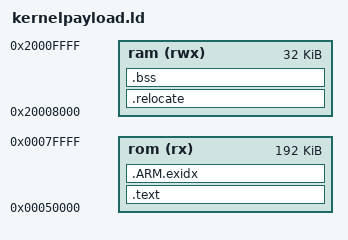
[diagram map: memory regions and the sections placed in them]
/*
 * This file is part of StormLoader, the Storm Bootloader
 *
 * StormLoader is free software: you can redistribute it and/or modify
 * it under the terms of the GNU General Public License as published by
 * the Free Software Foundation, either version 3 of the License, or
 * (at your option) any later version.
 *
 * StormLoader is distributed in the hope that it will be useful,
 * but WITHOUT ANY WARRANTY; without even the implied warranty of
 * MERCHANTABILITY or FITNESS FOR A PARTICULAR PURPOSE.  See the
 * GNU General Public License for more details.
 *
 * You should have received a copy of the GNU General Public License
 * along with Foobar.  If not, see <http://www.gnu.org/licenses/>.
 *  
 * Copyright 2014, Michael Andersen <m.andersen@eecs.berkeley.edu>
 *
 * This file is largely copied from the Atmel supplied linker scripts
 */

OUTPUT_FORMAT("elf32-littlearm", "elf32-littlearm", "elf32-littlearm")
OUTPUT_ARCH(arm)
SEARCH_DIR(.) 

/* Memory Spaces Definitions, 448K flash, 64K ram */
MEMORY
{
  rom (rx)  : ORIGIN = 0x00050000, LENGTH = 0x00030000
  ram (rwx) : ORIGIN = 0x20008000, LENGTH = 0x00008000
}

/* The stack size used by the application. NOTE: you need to adjust according to your application. */
__stack_size__ = 0x2000;
__ram_end__ = ORIGIN(ram) + LENGTH(ram) - 4;
_estack = __ram_end__ - 4;

/* Section Definitions */
SECTIONS
{
    stext = .;
    .text :
    {
        . = ALIGN(4);
        _sfixed = .;
        KEEP(*(.text._start .text._start2))
        *(.text .text.* .gnu.linkonce.t.*)
        *(.glue_7t) *(.glue_7)
        *(.rodata .rodata* .gnu.linkonce.r.*)
        *(.ARM.extab* .gnu.linkonce.armextab.*)

        /* Support C constructors, and C destructors in both user code
           and the C library. This also provides support for C++ code. */
        . = ALIGN(4);
        KEEP(*(.init))
        . = ALIGN(4);
        __preinit_array_start = .;
        KEEP (*(.preinit_array))
        __preinit_array_end = .;

        . = ALIGN(4);
        __init_array_start = .;
        KEEP (*(SORT(.init_array.*)))
        KEEP (*(.init_array))
        __init_array_end = .;

        . = ALIGN(0x4);
        KEEP (*crtbegin.o(.ctors))
        KEEP (*(EXCLUDE_FILE (*crtend.o) .ctors))
        KEEP (*(SORT(.ctors.*)))
        KEEP (*crtend.o(.ctors))

        . = ALIGN(4);
        KEEP(*(.fini))

        . = ALIGN(4);
        __fini_array_start = .;
        KEEP (*(.fini_array))
        KEEP (*(SORT(.fini_array.*)))
        __fini_array_end = .;

        KEEP (*crtbegin.o(.dtors))
        KEEP (*(EXCLUDE_FILE (*crtend.o) .dtors))
        KEEP (*(SORT(.dtors.*)))
        KEEP (*crtend.o(.dtors))

        . = ALIGN(4);
        _efixed = .;            /* End of text section */
    } > rom

    /* .ARM.exidx is sorted, so has to go in its own output section.  */
    PROVIDE_HIDDEN (__exidx_start = .);
    .ARM.exidx :
    {
      *(.ARM.exidx* .gnu.linkonce.armexidx.*)
    } > rom
    PROVIDE_HIDDEN (__exidx_end = .);

    . = ALIGN(4);
    _etext = .;
    etext = .;

    .relocate : AT (_etext)
    {
        . = ALIGN(4);
        _srelocate = .;
        *(.ramfunc .ramfunc.*);
        *(.data .data.*);
        . = ALIGN(4);
        _erelocate = .;
    } > ram

    /* .bss section which is used for uninitialized data */
    .bss (NOLOAD) :
    {
        . = ALIGN(4);
        _sbss = . ;
        __bss_start__ = .;
        _szero = .;
        *(.bss .bss.*)
        *(COMMON)
        . = ALIGN(4);
        _ebss = . ;
        __bss_end__ = .;
        _ezero = .;
    } > ram

    . = ALIGN(4);
    _end = . ;
    end = .;
}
